# Template register map
Vendor: VendorName Co.Ltd; Series: SeriesName; File version: 1.2
CPU: CM7 r0p1, little endian, MPU, FPU, 4 interrupt priority bits
Registers are 32-bit, read-write, no defined reset value unless marked. A register's access mark holds for its fields unless they carry their own. Offsets are from the block's base; [hi:lo] are bit positions; {n}, {i} and the like mark numbered series.

## ADCARESULT — Analog-to-Digital Converter A Result
Base 0x400A3000
Same registers: ADCBRESULT 0x400A3400, ADCCRESULT 0x400A3800, ADCDRESULT 0x400A3C00
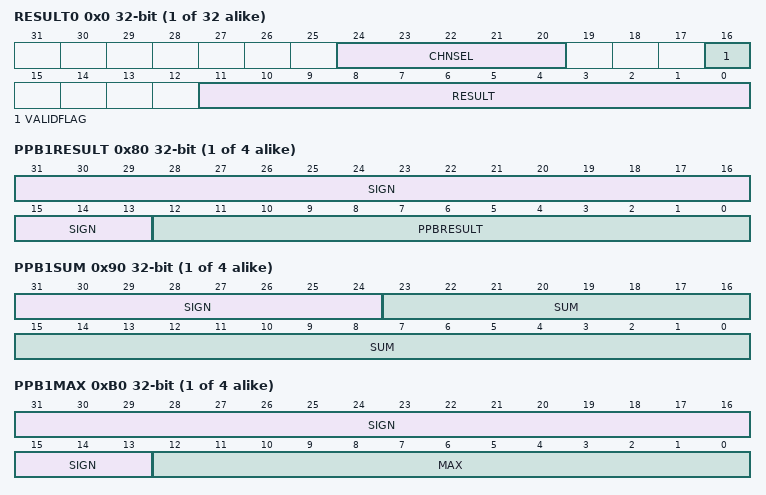
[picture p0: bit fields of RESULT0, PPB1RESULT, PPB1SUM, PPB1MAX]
{0x0+4i} RESULT{i} ro (i=0..31) — ADC result{i} register
  [24:20] CHNSEL — ADCARESULT CHNSEL[4:0] bit: SOC{i} channel selection
  [16] VALIDFLAG — ADCARESULT VALIDFLAG bit: data validity flag
  [11:0] RESULT — ADCARESULT RESULT[11:0] bit: the conversion result of the selected channel by SOC{i}
{0x7C+4i} PPB{i}RESULT ro (i=1..4) — ADC PPB{i} result register
  [31:13] SIGN — ADCARESULT SIGN[18:0] bit: sign extension bit
  [12:0] PPBRESULT — ADCARESULT PPBRESULT[12:0] bit: PPB{i} post-processing result
{0x88+8i} PPB{i}SUM ro (i=1..4) — ADC PPB{i} sum register
  [31:24] SIGN — ADCARESULT SIGN[7:0] bit: sign extension bit
  [23:0] SUM — ADCARESULT SUM[23:0] bit: PPB{i} post-processing final sum result
{0x8C+8i} PPB{i}COUNT ro (i=1..4) — ADC PPB{i} count register
  [9:0] COUNT — ADCARESULT COUNT[9:0] bit: PPB{i} post-processing final count
{0xA0+0x10*i} PPB{i}MAX ro (i=1..4) — ADC PPB{i} max register
  [31:13] SIGN — ADCARESULT SIGN[18:0] bit: sign extension bit
  [12:0] MAX — ADCARESULT MAX[12:0] bit: PPB{i} post-processing final maxinum value
{0xA4+0x10*i} PPB{i}MAXI ro (i=1..4) — ADC PPB{i} max index register
  [9:0] MAXI — ADCARESULT MAXI[9:0] bit: PPB{i} post-processing final maxinum value index
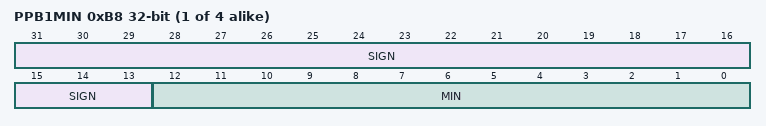
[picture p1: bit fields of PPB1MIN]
{0xA8+0x10*i} PPB{i}MIN ro (i=1..4) — ADC PPB{i} min register
  [31:13] SIGN — ADCARESULT SIGN[18:0] bit: sign extension bit
  [12:0] MIN — ADCARESULT MIN[12:0] bit: PPB{i} post-processing final mininum value
{0xAC+0x10*i} PPB{i}MINI ro (i=1..4) — ADC PPB{i} min index register
  [9:0] MINI — ADCARESULT MINI[9:0] bit: PPB{i} post-processing final mininum value index

## ADCSAFETYCHKAGG1 — Analog-to-Digitial Safety Checker Aggregate 1
Base 0x40038000
Same registers: ADCSAFETYCHKAGG2 0x40038100
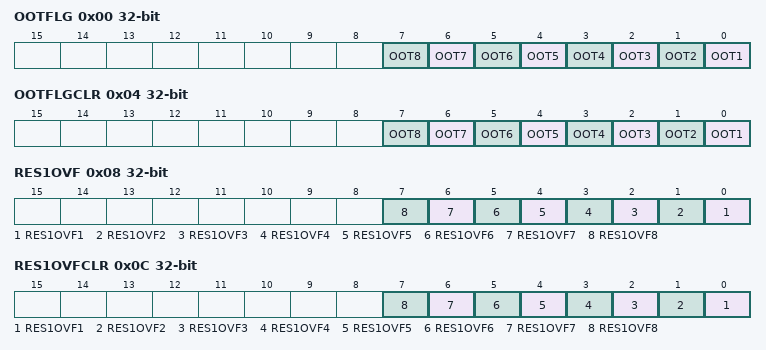
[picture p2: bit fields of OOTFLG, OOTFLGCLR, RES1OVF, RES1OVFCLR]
0x00 OOTFLG ro — ADCSAFETYCHK_AGG out of tolerance flag register
  [n-1] OOT{n} (n=1..8) — ADCSAFETYCHKAGG OOT{n} bit: ADC result safety checker {n} out of tolerance limit flag
0x04 OOTFLGCLR wo — ADCSAFETYCHK_AGG out of tolerance flag clear register
  [n-1] OOT{n} (n=1..8) — ADCSAFETYCHKAGG OOT{n} bit: ADC result safety checker {n} out of tolerance limit flag clear bit
0x08 RES1OVF ro — ADCSAFETYCHK_AGG result1 overflow flag register
  [n-1] RES1OVF{n} (n=1..8) — ADCSAFETYCHKAGG RES1OVF{n} bit: ADC result safety checker {n} result 1 overflow flag
0x0C RES1OVFCLR wo — ADCSAFETYCHK_AGG result1 overflow flag clear register
  [n-1] RES1OVF{n} (n=1..8) — ADCSAFETYCHKAGG RES1OVF{n} bit: ADC result safety checker {n} result 1 overflow flag clear bit
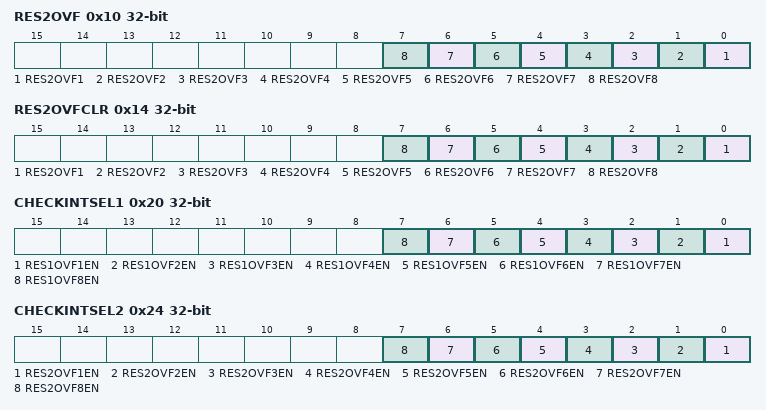
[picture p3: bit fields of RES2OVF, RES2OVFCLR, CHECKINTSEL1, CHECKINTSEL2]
0x10 RES2OVF ro — ADCSAFETYCHK_AGG result2 overflow flag register
  [n-1] RES2OVF{n} (n=1..8) — ADCSAFETYCHKAGG RES2OVF{n} bit: ADC result safety checker {n} result 2 overflow flag
0x14 RES2OVFCLR wo — ADCSAFETYCHK_AGG result2 overflow flag clear register
  [n-1] RES2OVF{n} (n=1..8) — ADCSAFETYCHKAGG RES2OVF{n} bit: ADC result safety checker {n} result 2 overflow flag clear bit
0x18 CHECKINTFLG ro — ADCSAFETYCHK_AGG interrupt flag register
  [0] CHECKINT — ADCSAFETYCHKAGG CHECKINT bit: ADC result safety checker subsystem interrupt flag
0x1C CHECKINTFLGCLR wo — ADCSAFETYCHK_AGG interrupt flag clear register
  [0] CHECKINTCLR — ADCSAFETYCHKAGG CHECKINTCLR bit: ADC result safety checker subsystem interrupt flag clear bit
0x20 CHECKINTSEL1 — ADCSAFETYCHK_AGG interrupt selection register1
  [n-1] RES1OVF{n}EN (n=1..8) — ADCSAFETYCHKAGG RES1OVF{n}EN bit: the RES1OVF of CHECK{n} as the module interrupt source enable
0x24 CHECKINTSEL2 — ADCSAFETYCHK_AGG interrupt selection register2
  [n-1] RES2OVF{n}EN (n=1..8) — ADCSAFETYCHKAGG RES2OVF{n}EN bit: the RES2OVF of CHECK{n} as the module interrupt source enable
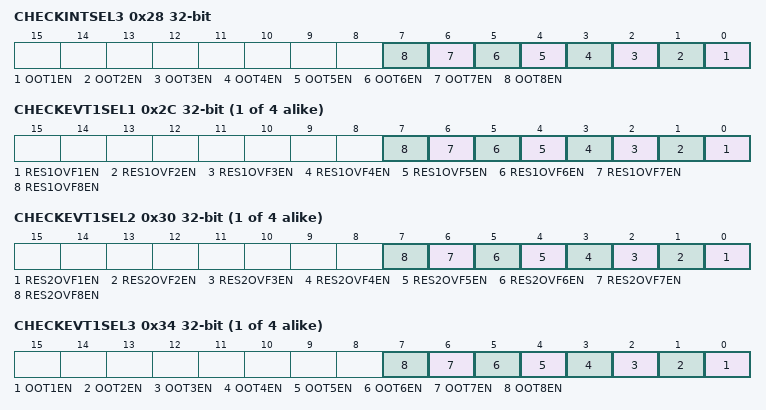
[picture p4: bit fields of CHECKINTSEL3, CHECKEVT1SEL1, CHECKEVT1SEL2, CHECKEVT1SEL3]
0x28 CHECKINTSEL3 — ADCSAFETYCHK_AGG interrupt selection register3
  [n-1] OOT{n}EN (n=1..8) — ADCSAFETYCHKAGG OOT{n}EN bit: the OOT{n} of CHECK{n} as the module interrupt source enable
{0x20+0xC*i} CHECKEVT{i}SEL1 (i=1..4) — ADCSAFETYCHK_AGG check event{i} selection register1
  [n-1] RES1OVF{n}EN (n=1..8) — ADCSAFETYCHKAGG RES1OVF{n}EN bit: the RES1OVF of CHECK{n} as the module output event {i}'s event source enable
{0x24+0xC*i} CHECKEVT{i}SEL2 (i=1..4) — ADCSAFETYCHK_AGG check event{i} selection register2
  [n-1] RES2OVF{n}EN (n=1..8) — ADCSAFETYCHKAGG RES2OVF{n}EN bit: the RES2OVF of CHECK{n} as the module output event {i}'s event source enable
{0x28+0xC*i} CHECKEVT{i}SEL3 (i=1..4) — ADCSAFETYCHK_AGG check event{i} selection register3
  [n-1] OOT{n}EN (n=1..8) — ADCSAFETYCHKAGG OOT{n}EN bit: the OOT{n} of CHECK{n} as the module output event {i}'s event source enable
